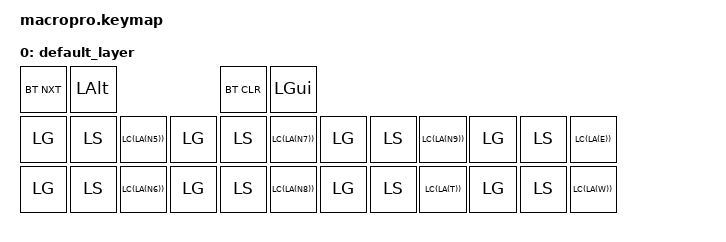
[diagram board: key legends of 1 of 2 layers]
#include <behaviors.dtsi>
#include <dt-bindings/zmk/keys.h>
#include <dt-bindings/zmk/bt.h>

#define DEFAULT 0
#define BT     1

/ {

    behaviors {
        rot_kp: rot_kp {
            compatible = "zmk,behavior-sensor-rotate-var";
            label = "rot_kp";
            #sensor-binding-cells = <2>;
            bindings = <&kp>, <&kp>;
        };

        rot_macro: rot_macro {
            compatible = "zmk,behavior-sensor-rotate-var";
            label = "rot_macro";
            #sensor-binding-cells = <2>;
            bindings = <&macropro>, <&macropro>;
        };
    };

    macros {
        macropro: macropro {
            label = "macropro";
            compatible = "zmk,behavior-macro";
            #binding-cells = <0>;
            bindings
                = <&macro_press &kp LEFT_COMMAND>
                , <&macro_press &kp LEFT_SHIFT>
                , <&macro_press &kp LEFT_ALT>
                , <&macro_press &kp LEFT_CONTROL>
                , <&macro_tap &kp NUMBER_1>
                , <&macro_release &kp LEFT_COMMAND>
                , <&macro_release &kp LEFT_SHIFT>
                , <&macro_release &kp LEFT_ALT>
                , <&macro_release &kp LEFT_CONTROL>
                ;
        };
    };

    keymap {
        compatible = "zmk,keymap";

        default_layer {
            bindings = <
                &bt BT_NXT &kp LEFT_ALT &bt BT_CLR &kp LEFT_GUI
                &kp LG(LS(LC(LA(N5)))) &kp LG(LS(LC(LA(N7)))) &kp LG(LS(LC(LA(N9)))) &kp LG(LS(LC(LA(E))))
                &kp LG(LS(LC(LA(N6)))) &kp LG(LS(LC(LA(N8)))) &kp LG(LS(LC(LA(T)))) &kp LG(LS(LC(LA(W))))
            >;
            sensor-bindings = <&rot_kp TAB LS(TAB) &rot_kp RIGHT_ARROW LEFT_ARROW &rot_kp TAB LS(TAB) &rot_kp LG(LS(RIGHT_ARROW)) LG(LS(LEFT_ARROW))>;
        };

        bt_layer {
            bindings = <
                &none   &bootloader
                &none   &bt BT_CLR
            >;
            sensor-bindings = <&rot_kp LEFT_ARROW RIGHT_ARROW &rot_kp UP_ARROW DOWN_ARROW>;
        };
    };
};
